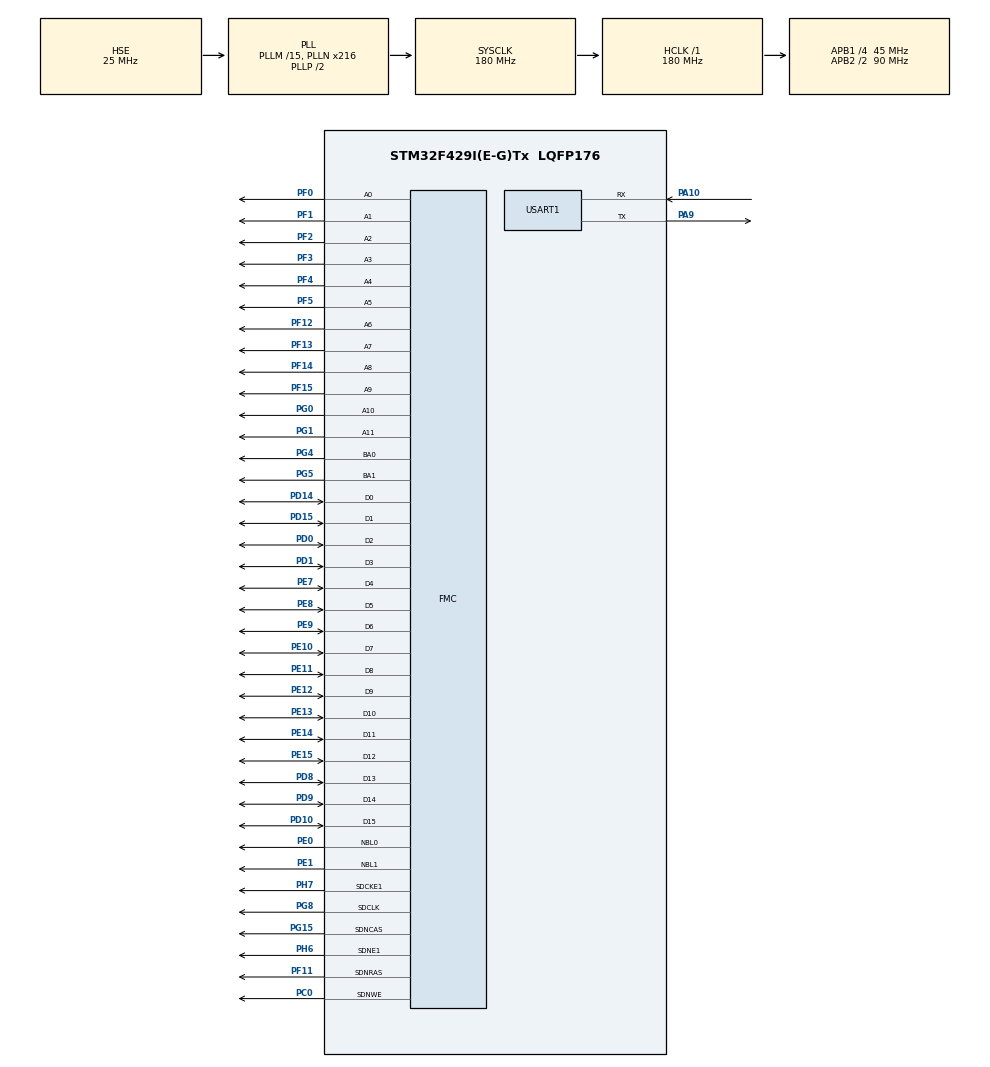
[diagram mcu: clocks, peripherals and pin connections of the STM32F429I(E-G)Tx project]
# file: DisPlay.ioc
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FMC.CASLatency1=FMC_SDRAM_CAS_LATENCY_2
FMC.ExitSelfRefreshDelay1=7
FMC.LoadToActiveDelay1=2
FMC.RCDDelay1=2
FMC.RPDelay1=2
FMC.RPDelay2=2
FMC.ReadBurst1=FMC_SDRAM_RBURST_DISABLE
FMC.ReadPipeDelay1=FMC_SDRAM_RPIPE_DELAY_1
FMC.ReadPipeDelay2=FMC_SDRAM_RPIPE_DELAY_1
FMC.RowCycleDelay1=6
FMC.RowCycleDelay2=6
FMC.SDClockPeriod1=FMC_SDRAM_CLOCK_PERIOD_2
FMC.SDClockPeriod2=FMC_SDRAM_CLOCK_PERIOD_2
FMC.SelfRefreshTime1=4
FMC.WriteRecoveryTime1=2
Mcu.Family=STM32F4
Mcu.Name=STM32F429I(E-G)Tx
Mcu.Package=LQFP176
NVIC.PriorityGroup=NVIC_PRIORITYGROUP_4
PA10.Mode=Asynchronous
PA10.Signal=USART1_RX
PA13.Mode=Serial_Wire
PA13.Signal=SYS_JTMS-SWDIO
PA14.Mode=Serial_Wire
PA14.Signal=SYS_JTCK-SWCLK
PA9.Mode=Asynchronous
PA9.Signal=USART1_TX
PC0.Signal=FMC_SDNWE
PD0.Signal=FMC_D2_DA2
PD1.Signal=FMC_D3_DA3
PD10.Signal=FMC_D15_DA15
PD14.Signal=FMC_D0_DA0
PD15.Signal=FMC_D1_DA1
PD8.Signal=FMC_D13_DA13
PD9.Signal=FMC_D14_DA14
PE0.Signal=FMC_NBL0
PE1.Signal=FMC_NBL1
PE10.Signal=FMC_D7_DA7
PE11.Signal=FMC_D8_DA8
PE12.Signal=FMC_D9_DA9
PE13.Signal=FMC_D10_DA10
PE14.Signal=FMC_D11_DA11
PE15.Signal=FMC_D12_DA12
PE7.Signal=FMC_D4_DA4
PE8.Signal=FMC_D5_DA5
PE9.Signal=FMC_D6_DA6
PF0.Signal=FMC_A0
PF1.Signal=FMC_A1
PF11.Signal=FMC_SDNRAS
PF12.Signal=FMC_A6
PF13.Signal=FMC_A7
PF14.Signal=FMC_A8
PF15.Signal=FMC_A9
PF2.Signal=FMC_A2
PF3.Signal=FMC_A3
PF4.Signal=FMC_A4
PF5.Signal=FMC_A5
PG0.Signal=FMC_A10
PG1.Signal=FMC_A11
PG15.Signal=FMC_SDNCAS
PG4.Signal=FMC_A14_BA0
PG5.Signal=FMC_A15_BA1
PG8.Signal=FMC_SDCLK
PH0/OSC_IN.Mode=HSE-External-Oscillator
PH0/OSC_IN.Signal=RCC_OSC_IN
PH1/OSC_OUT.Mode=HSE-External-Oscillator
PH1/OSC_OUT.Signal=RCC_OSC_OUT
PH6.Mode=SdramChipSelect2_1
PH6.Signal=FMC_SDNE1
PH7.Mode=SdramChipSelect2_1
PH7.Signal=FMC_SDCKE1
ProjectManager.HeapSize=0x200
ProjectManager.StackSize=0x400
ProjectManager.TargetToolchain=MDK-ARM V5.27
RCC.48MHZClocksFreq_Value=90000000
RCC.AHBFreq_Value=180000000
RCC.APB1CLKDivider=RCC_HCLK_DIV4
RCC.APB1Freq_Value=45000000
RCC.APB1TimFreq_Value=90000000
RCC.APB2CLKDivider=RCC_HCLK_DIV2
RCC.APB2Freq_Value=90000000
RCC.APB2TimFreq_Value=180000000
RCC.CortexFreq_Value=180000000
RCC.HCLKFreq_Value=180000000
RCC.HSE_VALUE=25000000
RCC.HSI_VALUE=16000000
RCC.LSE_VALUE=32768
RCC.PLLM=15
RCC.PLLN=216
RCC.PLLSourceVirtual=RCC_PLLSOURCE_HSE
RCC.SYSCLKFreq_VALUE=180000000
RCC.SYSCLKSource=RCC_SYSCLKSOURCE_PLLCLK
RCC.VCOOutputFreq_Value=360000000
SH.FMC_A0.0=FMC_A0,12b-sda1
SH.FMC_A1.0=FMC_A1,12b-sda1
SH.FMC_A10.0=FMC_A10,12b-sda1
SH.FMC_A11.0=FMC_A11,12b-sda1
SH.FMC_A14_BA0.0=FMC_BA0,FourSdramBanks1
SH.FMC_A15_BA1.0=FMC_BA1,FourSdramBanks1
SH.FMC_A2.0=FMC_A2,12b-sda1
SH.FMC_A3.0=FMC_A3,12b-sda1
SH.FMC_A4.0=FMC_A4,12b-sda1
SH.FMC_A5.0=FMC_A5,12b-sda1
SH.FMC_A6.0=FMC_A6,12b-sda1
SH.FMC_A7.0=FMC_A7,12b-sda1
SH.FMC_A8.0=FMC_A8,12b-sda1
SH.FMC_A9.0=FMC_A9,12b-sda1
SH.FMC_D0_DA0.0=FMC_D0,sd-16b-d1
SH.FMC_D10_DA10.0=FMC_D10,sd-16b-d1
SH.FMC_D11_DA11.0=FMC_D11,sd-16b-d1
SH.FMC_D12_DA12.0=FMC_D12,sd-16b-d1
SH.FMC_D13_DA13.0=FMC_D13,sd-16b-d1
SH.FMC_D14_DA14.0=FMC_D14,sd-16b-d1
SH.FMC_D15_DA15.0=FMC_D15,sd-16b-d1
SH.FMC_D1_DA1.0=FMC_D1,sd-16b-d1
SH.FMC_D2_DA2.0=FMC_D2,sd-16b-d1
SH.FMC_D3_DA3.0=FMC_D3,sd-16b-d1
SH.FMC_D4_DA4.0=FMC_D4,sd-16b-d1
SH.FMC_D5_DA5.0=FMC_D5,sd-16b-d1
SH.FMC_D6_DA6.0=FMC_D6,sd-16b-d1
SH.FMC_D7_DA7.0=FMC_D7,sd-16b-d1
SH.FMC_D8_DA8.0=FMC_D8,sd-16b-d1
SH.FMC_D9_DA9.0=FMC_D9,sd-16b-d1
SH.FMC_NBL0.0=FMC_NBL0,Sd2ByteEnable1
SH.FMC_NBL1.0=FMC_NBL1,Sd2ByteEnable1
SH.FMC_SDCLK.0=FMC_SDCLK,12b-sda1
SH.FMC_SDNCAS.0=FMC_SDNCAS,12b-sda1
SH.FMC_SDNRAS.0=FMC_SDNRAS,12b-sda1
SH.FMC_SDNWE.0=FMC_SDNWE,12b-sda1
USART1.VirtualMode=VM_ASYNC
board=custom

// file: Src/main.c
/* USER CODE BEGIN Header */
/**
  ******************************************************************************
  * @file           : main.c
  * @brief          : Main program body
  ******************************************************************************
  * @attention
  *
  * <h2><center>&copy; Copyright (c) 2021 STMicroelectronics.
  * All rights reserved.</center></h2>
  *
  * This software component is licensed by ST under BSD 3-Clause license,
  * the "License"; You may not use this file except in compliance with the
  * License. You may obtain a copy of the License at:
  *                        opensource.org/licenses/BSD-3-Clause
  *
  ******************************************************************************
  */
/* USER CODE END Header */
#include "main.h"
#include "usart.h"
#include "gpio.h"
#include "fmc.h"

void SystemClock_Config(void);

int main(void)
{
  /* USER CODE BEGIN 1 */
  uint8_t temp = 1,temp1 = 'A';
  uint32_t *pSDRAM= (uint32_t*)0xD0000000;
  uint32_t buffer[] = {0xABCDEF98,0xABCDEF97,0xABCDEF96};
  uint32_t buffer1[3];
  /* USER CODE END 1 */

  /* MCU Configuration--------------------------------------------------------*/

  /* Reset of all peripherals, Initializes the Flash interface and the Systick. */
  HAL_Init();

  /* Configure the system clock */
  SystemClock_Config();

  /* Initialize all configured peripherals */
  MX_GPIO_Init();
  MX_FMC_Init();
  MX_USART1_UART_Init();
  /* USER CODE BEGIN 2 */
  printf("DisPlay!!!\n");
  while(HAL_SDRAM_Write_8b(&hsdram1,pSDRAM,&temp1,1) != HAL_OK);
  printf("Write to successful!!!\n");

  while(HAL_SDRAM_Read_8b(&hsdram1,pSDRAM,&temp,1) != HAL_OK);
  printf("%c\n",temp);
  SDRAM_WriteBuffer(buffer,0,3);
  SDRAM_ReadBuffer(buffer1,0,3);
  printf("%x\n",buffer1[0]);
  printf("%x\n",buffer1[1]);
  printf("%x\n",buffer1[2]);
  /* USER CODE END 2 */

  /* Infinite loop */
  while (1)
  {

  }
}

void SystemClock_Config(void)
{
  RCC_OscInitTypeDef RCC_OscInitStruct = {0};
  RCC_ClkInitTypeDef RCC_ClkInitStruct = {0};

  /** Configure the main internal regulator output voltage
  */
  __HAL_RCC_PWR_CLK_ENABLE();
  __HAL_PWR_VOLTAGESCALING_CONFIG(PWR_REGULATOR_VOLTAGE_SCALE1);
  /** Initializes the RCC Oscillators according to the specified parameters
  * in the RCC_OscInitTypeDef structure.
  */
  RCC_OscInitStruct.OscillatorType = RCC_OSCILLATORTYPE_HSE;
  RCC_OscInitStruct.HSEState = RCC_HSE_ON;
  RCC_OscInitStruct.PLL.PLLState = RCC_PLL_ON;
  RCC_OscInitStruct.PLL.PLLSource = RCC_PLLSOURCE_HSE;
  RCC_OscInitStruct.PLL.PLLM = 15;
  RCC_OscInitStruct.PLL.PLLN = 216;
  RCC_OscInitStruct.PLL.PLLP = RCC_PLLP_DIV2;
  RCC_OscInitStruct.PLL.PLLQ = 4;
  if (HAL_RCC_OscConfig(&RCC_OscInitStruct) != HAL_OK)
  {
    Error_Handler();
  }
  /** Activate the Over-Drive mode
  */
  if (HAL_PWREx_EnableOverDrive() != HAL_OK)
  {
    Error_Handler();
  }
  /** Initializes the CPU, AHB and APB buses clocks
  */
  RCC_ClkInitStruct.ClockType = RCC_CLOCKTYPE_HCLK|RCC_CLOCKTYPE_SYSCLK
                              |RCC_CLOCKTYPE_PCLK1|RCC_CLOCKTYPE_PCLK2;
  RCC_ClkInitStruct.SYSCLKSource = RCC_SYSCLKSOURCE_PLLCLK;
  RCC_ClkInitStruct.AHBCLKDivider = RCC_SYSCLK_DIV1;
  RCC_ClkInitStruct.APB1CLKDivider = RCC_HCLK_DIV4;
  RCC_ClkInitStruct.APB2CLKDivider = RCC_HCLK_DIV2;

  if (HAL_RCC_ClockConfig(&RCC_ClkInitStruct, FLASH_LATENCY_5) != HAL_OK)
  {
    Error_Handler();
  }
}

void Error_Handler(void)
{
  __disable_irq();
  while (1)
  {
  }
}

/************************ (C) COPYRIGHT STMicroelectronics *****END OF FILE****/
